VERSION ""

NS_ :

BS_:

BU_: Vehicle_ECU Driver
VAL_TABLE_ drive_mode 2 "스포츠주행" 1 "에코주행" 0 "기본주행" ;
VAL_TABLE_ Gear_status 3 "중립" 2 "후진" 1 "주행" 0 "파킹" ;

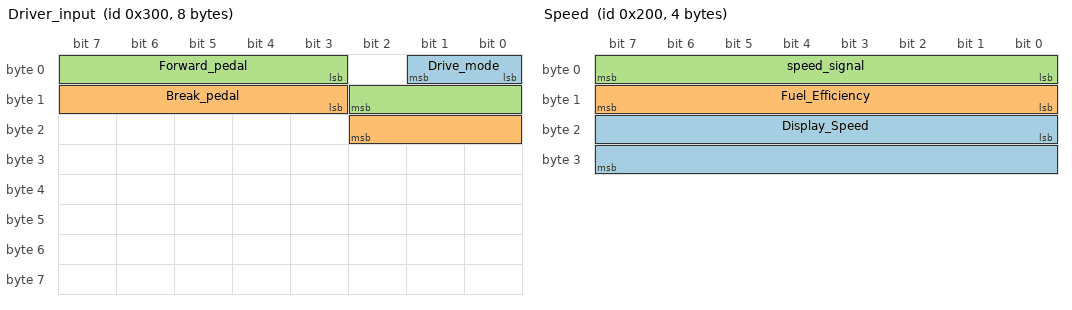
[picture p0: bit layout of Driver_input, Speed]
BO_ 768 Driver_input: 8 Driver
 SG_ Drive_mode : 0|2@1+ (1,0) [0|3] ""  Vehicle_ECU
 SG_ Break_pedal : 11|8@1+ (1,0) [0|100] ""  Vehicle_ECU
 SG_ Forward_pedal : 3|8@1+ (1,0) [0|100] ""  Vehicle_ECU

BO_ 512 Speed: 4 Vehicle_ECU
 SG_ Display_Speed : 16|16@1- (0.1,0) [-100|250] "km/h"  Driver
 SG_ Fuel_Efficiency : 8|8@1+ (0.1,0) [0|50] "Km/L"  Driver
 SG_ speed_signal : 0|8@1+ (1,0) [0|250] "Km/h"  Driver

BO_ 256 GearControl: 2 Driver
 SG_ Gear : 4|4@1+ (1,0) [0|3] ""  Vehicle_ECU

EV_ EnvKlemme30: 0 [0|1] "" 1 1 DUMMY_NODE_VECTOR0 Vector__XXX;

EV_ EnvKlemme15: 0 [0|1] "" 0 2 DUMMY_NODE_VECTOR0 Vector__XXX;

CM_ BO_ 512 "주행";
CM_ BO_ 256 "운전자의 기어선택.";
CM_ SG_ 256 Gear "0 파킹 1 주행 2 후진 3 주행";
BA_DEF_ BU_  "NodeLayerModules" STRING ;
BA_DEF_ BO_  "GenMsgILSupport" ENUM  "No","Yes";
BA_DEF_  "NmBaseAddress" HEX 1024 1087;
BA_DEF_  "BusType" STRING ;
BA_DEF_ BO_  "GenMsgSendType" ENUM  "Cyclic","NotUsed","NotUsed","NotUsed","NotUsed","NotUsed","NotUsed","IfActive","NoMsgSendType","NotUsed","vector_leerstring";
BA_DEF_ SG_  "GenSigSendType" ENUM  "Cyclic","OnWrite","OnWriteWithRepetition","OnChange","OnChangeWithRepetition","IfActive","IfActiveWithRepetition","NoSigSendType","NotUsed","NotUsed","NotUsed","NotUsed","NotUsed";
BA_DEF_DEF_  "NodeLayerModules" "CANoeILNLVector.dll";
BA_DEF_DEF_  "GenMsgILSupport" "Yes";
BA_DEF_DEF_  "NmBaseAddress" 1024;
BA_DEF_DEF_  "BusType" "";
BA_DEF_DEF_  "GenMsgSendType" "NoMsgSendType";
BA_DEF_DEF_  "GenSigSendType" "Cyclic";
BA_ "BusType" "CAN";
VAL_ 768 Drive_mode 2 "스포츠주행" 1 "에코주행" 0 "기본주행" ;
VAL_ 256 Gear 3 "중립" 2 "후진" 1 "주행" 0 "파킹" ;
